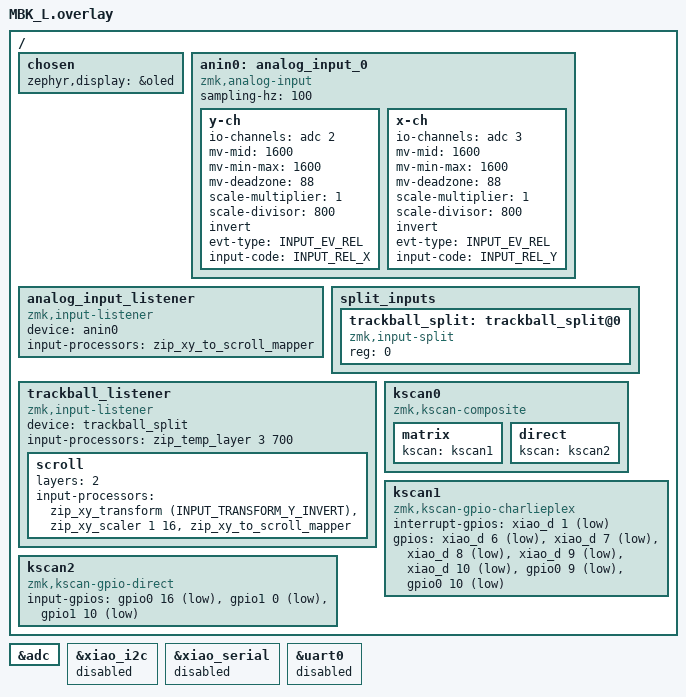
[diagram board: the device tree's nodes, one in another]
#include <dt-bindings/zmk/bt.h>
#include <input/processors.dtsi>
#include <dt-bindings/zmk/input_transform.h>
#include <zephyr/dt-bindings/input/input-event-codes.h>
#include "MKB_pinctrl_L.dtsi"
#include "MKB.dtsi"

&adc {
	status = "okay";
};

/ {
    chosen {
        zephyr,display = &oled;
    };
    
    anin0: analog_input_0 {
        compatible = "zmk,analog-input";
        sampling-hz = <100>;
        y-ch {
            io-channels = <&adc 2>;
            mv-mid = <1600>;
            mv-min-max = <1600>;
            mv-deadzone = <88>;
            scale-multiplier = <1>;
            scale-divisor = <800>;
            invert;
            evt-type = <INPUT_EV_REL>;
            input-code = <INPUT_REL_X>;
        };
        x-ch {
            io-channels = <&adc 3>;
            mv-mid = <1600>;
            mv-min-max = <1600>;
            mv-deadzone = <88>;
            scale-multiplier = <1>;
            scale-divisor = <800>;
            invert;
            evt-type = <INPUT_EV_REL>;
            input-code = <INPUT_REL_Y>;
        };
    };
    
    analog_input_listener {
        status = "okay";
        compatible = "zmk,input-listener";
        device = <&anin0>;
        input-processors = <&zip_xy_to_scroll_mapper>;
    };

    split_inputs {
        #address-cells = <1>;
        #size-cells = <0>;

        trackball_split: trackball_split@0 {
            compatible = "zmk,input-split";
            reg = <0>;
        };
    };

    trackball_listener: trackball_listener {
        compatible = "zmk,input-listener";
        status = "disabled";
        device = <&trackball_split>;
    };
    
    kscan0: kscan0 {
        compatible = "zmk,kscan-composite";
        matrix {
            kscan = <&kscan1>;
        };
        direct {
            kscan = <&kscan2>;
        };
    };

    kscan1: kscan1 {
        compatible = "zmk,kscan-gpio-charlieplex";
        interrupt-gpios = <&xiao_d 1 (GPIO_ACTIVE_LOW)>;
        gpios
            = <&xiao_d 6 (GPIO_ACTIVE_LOW)>
            , <&xiao_d 7 (GPIO_ACTIVE_LOW)>
            , <&xiao_d 8 (GPIO_ACTIVE_LOW)>
            , <&xiao_d 9 (GPIO_ACTIVE_LOW)>
            , <&xiao_d 10 (GPIO_ACTIVE_LOW)>
            , <&gpio0 9 GPIO_ACTIVE_LOW>
            , <&gpio0 10 GPIO_ACTIVE_LOW>
            ;
    };

    kscan2: kscan2 {
        compatible = "zmk,kscan-gpio-direct";
        input-gpios
            = <&gpio0 16 (GPIO_ACTIVE_LOW)>
            , <&gpio1 0 (GPIO_ACTIVE_LOW)>
            , <&gpio1 10 (GPIO_ACTIVE_LOW)>
            ;
    };
};

&trackball_listener {
    status = "okay";
    input-processors = <&zip_temp_layer 3 700>;

    scroll {
        layers = <2>;
        input-processors = <&zip_xy_transform (INPUT_TRANSFORM_Y_INVERT)>, <&zip_xy_scaler 1 16>, <&zip_xy_to_scroll_mapper>;
    };
};

&xiao_i2c { status = "disabled"; };
&xiao_serial { status = "disabled"; };
&uart0 { status = "disabled";};
